AUTOSAR XML (schema 4-0-3)
standard types defined: uint8, Boolean, UInt16, UInt8
package /AUTOSAR_Platform/DataConstrs
  range DC_Boolean: raw 0..1
  range DC_UInt16: raw 0..65535
  range DC_UInt8: raw 0..255
package /DataTypes/Units
  unit NoUnit1: display-name=NoUnit, factor-si-to-unit=1, offset-si-to-unit=0
package /PATAC/Facility/DataTypes/Implementation
  compu method COMPU_Boolean: 0=FALSE, 1=TRUE
  unit NoUnit: factor-si-to-unit=1, offset-si-to-unit=0
package /PATAC/MSM/DataTypes/ImplementationDataTypes
  impl type IfVeSMSeStNumConfig: category=VALUE, base-type=UInt8, sw-calibration-access=READ-ONLY, compu {0=SeatNum4Config, 1=SeatNum6Config, 2=SeatNum7Config, 3=SeatNum4PConfig, 4=SeatNumNDLBLow, 5=SeatNumNDLBHigh}, type-emitter=RTE
package /PATAC/MSM/ModeAdjust
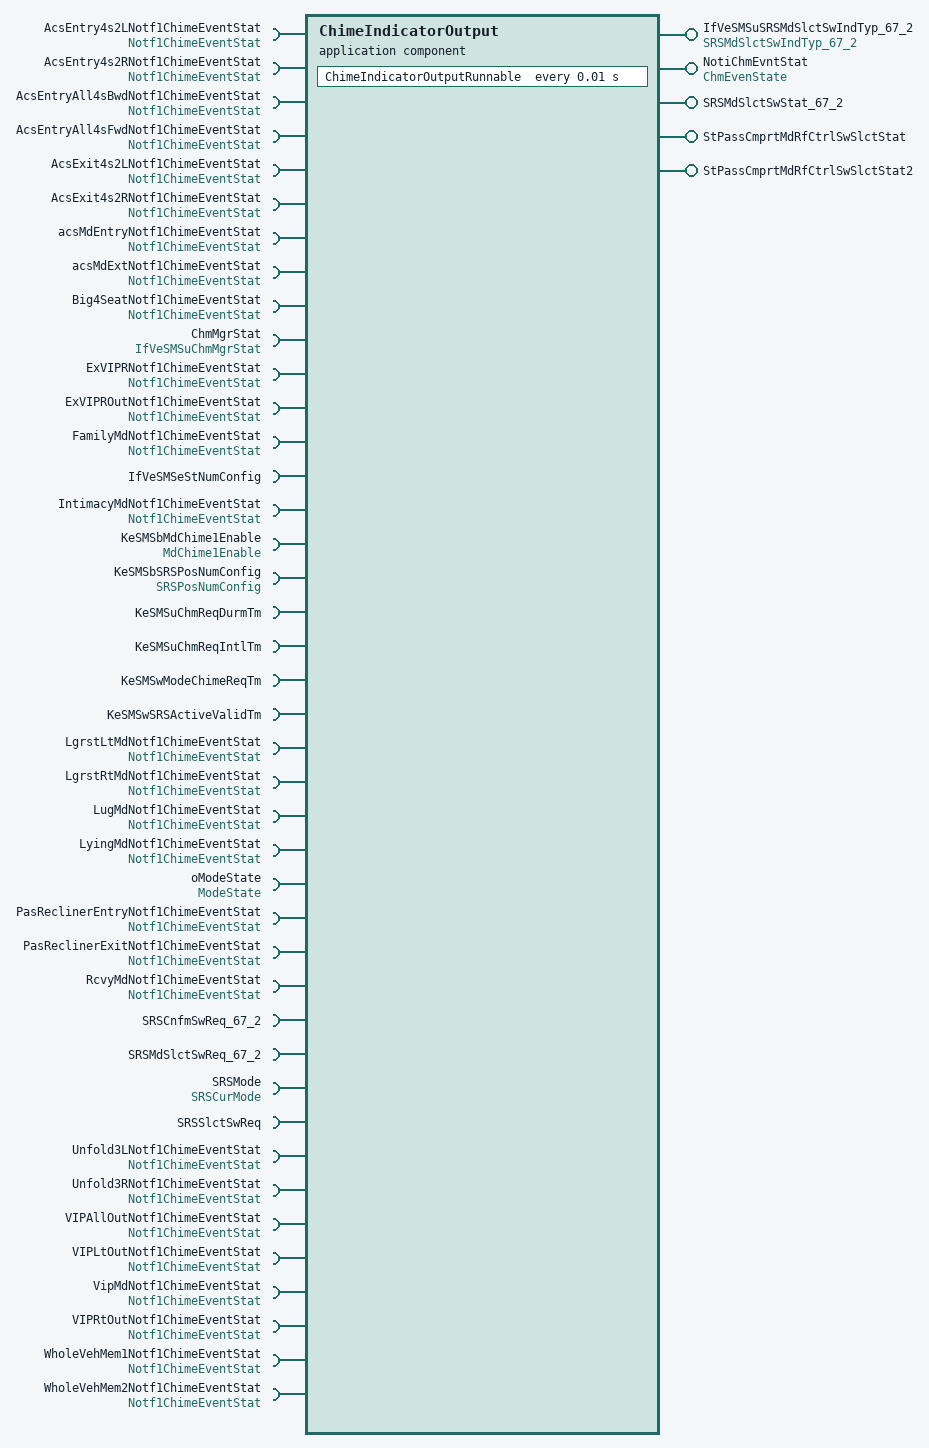
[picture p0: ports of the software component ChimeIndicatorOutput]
  application sw component type ChimeIndicatorOutput
    5 x provide port:
      IfVeSMSuSRSMdSlctSwIndTyp_67_2: nonqueued-sender-com-spec{data-element=SRSMdSlctSwIndTyp_67_2/Val, init-value=1}, provided-interface=SRSMdSlctSwIndTyp_67_2
      NotiChmEvntStat: nonqueued-sender-com-spec{data-element=ChmEvenState/Val, init-value=0}, provided-interface=ChmEvenState
      SRSMdSlctSwStat_67_2: nonqueued-sender-com-spec{data-element=SRSMdSlctSwStat_67_2/Val, init-value=0}, provided-interface=SRSMdSlctSwStat_67_2
      StPassCmprtMdRfCtrlSwSlctStat: nonqueued-sender-com-spec{data-element=StPassCmprtMdRfCtrlSwSlctStat/Val, init-value=0}, provided-interface=StPassCmprtMdRfCtrlSwSlctStat
      StPassCmprtMdRfCtrlSwSlctStat2: nonqueued-sender-com-spec{data-element=StPassCmprtMdRfCtrlSwSlctStat2/Val, init-value=0}, provided-interface=StPassCmprtMdRfCtrlSwSlctStat2
    41 x require port:
      AcsEntry4s2LNotf1ChimeEventStat: nonqueued-receiver-com-spec{data-element=Notf1ChimeEventStat/Val, filter=data-filter-type=ALWAYS, init-value=ComSpeceda9e3ad_0fc6068a0470d301:0}, required-interface=Notf1ChimeEventStat
      AcsEntry4s2RNotf1ChimeEventStat: nonqueued-receiver-com-spec{data-element=Notf1ChimeEventStat/Val, filter=data-filter-type=ALWAYS, init-value=ComSpec8c573e42_0f1c7c18a14dbf66:0}, required-interface=Notf1ChimeEventStat
      AcsEntryAll4sBwdNotf1ChimeEventStat: nonqueued-receiver-com-spec{data-element=Notf1ChimeEventStat/Val, filter=data-filter-type=ALWAYS, init-value=ComSpec37c91717_b8c9f7bc704ff9d2:0}, required-interface=Notf1ChimeEventStat
      AcsEntryAll4sFwdNotf1ChimeEventStat: nonqueued-receiver-com-spec{data-element=Notf1ChimeEventStat/Val, filter=data-filter-type=ALWAYS, init-value=ComSpecd15f079f_e85a705a3cb0df53:0}, required-interface=Notf1ChimeEventStat
      AcsExit4s2LNotf1ChimeEventStat: nonqueued-receiver-com-spec{data-element=Notf1ChimeEventStat/Val, filter=data-filter-type=ALWAYS, init-value=ComSpec6bd96ec8_afd24b1b20c88edf:0}, required-interface=Notf1ChimeEventStat
      AcsExit4s2RNotf1ChimeEventStat: nonqueued-receiver-com-spec{data-element=Notf1ChimeEventStat/Val, filter=data-filter-type=ALWAYS, init-value=ComSpec9c4cc562_0f5ef71d88f0fd04:0}, required-interface=Notf1ChimeEventStat
      acsMdEntryNotf1ChimeEventStat: nonqueued-receiver-com-spec{data-element=Notf1ChimeEventStat/Val, filter=data-filter-type=ALWAYS, init-value=0}, required-interface=Notf1ChimeEventStat
      acsMdExtNotf1ChimeEventStat: nonqueued-receiver-com-spec{data-element=Notf1ChimeEventStat/Val, filter=data-filter-type=ALWAYS, init-value=ComSpec24494de9_edfa97ce43be2a3a:0}, required-interface=Notf1ChimeEventStat
      Big4SeatNotf1ChimeEventStat: nonqueued-receiver-com-spec{data-element=Notf1ChimeEventStat/Val, filter=data-filter-type=ALWAYS, init-value=0}, required-interface=Notf1ChimeEventStat
      ChmMgrStat: nonqueued-receiver-com-spec{data-element=IfVeSMSuChmMgrStat/Val, filter=data-filter-type=ALWAYS, init-value=ComSpec0ceab9e4_4a33521a3ee1a770:2}, required-interface=IfVeSMSuChmMgrStat
      ExVIPRNotf1ChimeEventStat: nonqueued-receiver-com-spec{data-element=Notf1ChimeEventStat/Val, filter=data-filter-type=ALWAYS, init-value=0}, required-interface=Notf1ChimeEventStat
      ExVIPROutNotf1ChimeEventStat: nonqueued-receiver-com-spec{data-element=Notf1ChimeEventStat/Val, filter=data-filter-type=ALWAYS, init-value=0}, required-interface=Notf1ChimeEventStat
      FamilyMdNotf1ChimeEventStat: nonqueued-receiver-com-spec{data-element=Notf1ChimeEventStat/Val, filter=data-filter-type=ALWAYS, init-value=ComSpec92b47237_cd009972311b2162:0}, required-interface=Notf1ChimeEventStat
      IfVeSMSeStNumConfig: nonqueued-receiver-com-spec{data-element=IfVeSMSeStNumConfig/Val, filter=data-filter-type=ALWAYS, init-value=2}, required-interface=IfVeSMSeStNumConfig
      IntimacyMdNotf1ChimeEventStat: nonqueued-receiver-com-spec{data-element=Notf1ChimeEventStat/Val, filter=data-filter-type=ALWAYS, init-value=ComSpec3c33feb1_9314e4783a6c11b5:0}, required-interface=Notf1ChimeEventStat
      KeSMSbMdChime1Enable: parameter-require-com-spec{init-value=KeSMSbMdChime1Enable_Val:0, parameter=MdChime1Enable/Val}, required-interface=MdChime1Enable
      KeSMSbSRSPosNumConfig: parameter-require-com-spec{init-value=4, parameter=SRSPosNumConfig/Val}, required-interface=SRSPosNumConfig
      KeSMSuChmReqDurmTm: parameter-require-com-spec{init-value=KeSMSuChmReqDurmTm_Val:200, parameter=KeSMSuChmReqDurmTm/Val}, required-interface=KeSMSuChmReqDurmTm
      KeSMSuChmReqIntlTm: parameter-require-com-spec{init-value=KeSMSuChmReqIntlTm_Val:50, parameter=KeSMSuChmReqIntlTm/Val}, required-interface=KeSMSuChmReqIntlTm
      KeSMSwModeChimeReqTm: parameter-require-com-spec{init-value=KeSMSwModeChimeReqTm_Val:500, parameter=KeSMSwModeChimeReqTm/Val}, required-interface=KeSMSwModeChimeReqTm
      KeSMSwSRSActiveValidTm: parameter-require-com-spec{init-value=KeSMSwSRSActiveValidTm_Val:500, parameter=KeSMSwSRSActiveValidTm/Val}, required-interface=KeSMSwSRSActiveValidTm
      LgrstLtMdNotf1ChimeEventStat: nonqueued-receiver-com-spec{data-element=Notf1ChimeEventStat/Val, filter=data-filter-type=ALWAYS, init-value=ComSpecac8d8dad_acf652ffb0cb1279:0}, required-interface=Notf1ChimeEventStat
      LgrstRtMdNotf1ChimeEventStat: nonqueued-receiver-com-spec{data-element=Notf1ChimeEventStat/Val, filter=data-filter-type=ALWAYS, init-value=ComSpec3d6065d3_a539af7cf0176c3f:0}, required-interface=Notf1ChimeEventStat
      LugMdNotf1ChimeEventStat: nonqueued-receiver-com-spec{data-element=Notf1ChimeEventStat/Val, filter=data-filter-type=ALWAYS, init-value=ComSpec7c5dd238_74e99c6277d5e641:0}, required-interface=Notf1ChimeEventStat
      LyingMdNotf1ChimeEventStat: nonqueued-receiver-com-spec{data-element=Notf1ChimeEventStat/Val, filter=data-filter-type=ALWAYS, init-value=ComSpecd8b8ae0e_83cb297b15cbea14:0}, required-interface=Notf1ChimeEventStat
      oModeState: nonqueued-receiver-com-spec{data-element=ModeState/Val, filter=data-filter-type=ALWAYS, init-value=0}, required-interface=ModeState
      PasReclinerEntryNotf1ChimeEventStat: nonqueued-receiver-com-spec{data-element=Notf1ChimeEventStat/Val, filter=data-filter-type=ALWAYS, init-value=ComSpec7e4d3edc_7acc9f8f2009e728:0}, required-interface=Notf1ChimeEventStat
      PasReclinerExitNotf1ChimeEventStat: nonqueued-receiver-com-spec{data-element=Notf1ChimeEventStat/Val, filter=data-filter-type=ALWAYS, init-value=ComSpec9f4ab2cf_5d7cafcfdff2af21:0}, required-interface=Notf1ChimeEventStat
      RcvyMdNotf1ChimeEventStat: nonqueued-receiver-com-spec{data-element=Notf1ChimeEventStat/Val, filter=data-filter-type=ALWAYS, init-value=ComSpece6a37631_464cf6f791a15f13:0}, required-interface=Notf1ChimeEventStat
      SRSCnfmSwReq_67_2: nonqueued-receiver-com-spec{data-element=SRSCnfmSwReq_67_2/Val, filter=data-filter-type=ALWAYS, init-value=ComSpec9325e9e8_f7fd9485b93f3ffd:0}, required-interface=SRSCnfmSwReq_67_2
      SRSMdSlctSwReq_67_2: nonqueued-receiver-com-spec{data-element=SRSMdSlctSwReq_67_2/Val, filter=data-filter-type=ALWAYS, init-value=0}, required-interface=SRSMdSlctSwReq_67_2
      SRSMode: nonqueued-receiver-com-spec{data-element=SRSCurMode/Val, filter=data-filter-type=ALWAYS, init-value=0}, required-interface=SRSCurMode
      SRSSlctSwReq: nonqueued-receiver-com-spec{data-element=SRSSlctSwReq/Val, filter=data-filter-type=ALWAYS, init-value=0}, required-interface=SRSSlctSwReq
      Unfold3LNotf1ChimeEventStat: nonqueued-receiver-com-spec{data-element=Notf1ChimeEventStat/Val, filter=data-filter-type=ALWAYS, init-value=ComSpecd4722a82_9dfecf2406bed3a2:0}, required-interface=Notf1ChimeEventStat
      Unfold3RNotf1ChimeEventStat: nonqueued-receiver-com-spec{data-element=Notf1ChimeEventStat/Val, filter=data-filter-type=ALWAYS, init-value=ComSpec42213ac2_e56d2450b57cadc3:0}, required-interface=Notf1ChimeEventStat
      VIPAllOutNotf1ChimeEventStat: nonqueued-receiver-com-spec{data-element=Notf1ChimeEventStat/Val, filter=data-filter-type=ALWAYS, init-value=ComSpeccc961ebe_a596b23fd04396d1:0}, required-interface=Notf1ChimeEventStat
      VIPLtOutNotf1ChimeEventStat: nonqueued-receiver-com-spec{data-element=Notf1ChimeEventStat/Val, filter=data-filter-type=ALWAYS, init-value=ComSpecd5d8d36a_66b3bc886f3170c5:0}, required-interface=Notf1ChimeEventStat
      VipMdNotf1ChimeEventStat: nonqueued-receiver-com-spec{data-element=Notf1ChimeEventStat/Val, filter=data-filter-type=ALWAYS, init-value=ComSpec89e941d0_21fb21470bdd5603:0}, required-interface=Notf1ChimeEventStat
      VIPRtOutNotf1ChimeEventStat: nonqueued-receiver-com-spec{data-element=Notf1ChimeEventStat/Val, filter=data-filter-type=ALWAYS, init-value=ComSpec834e1dd5_b69ddf5dd0ce9610:0}, required-interface=Notf1ChimeEventStat
      WholeVehMem1Notf1ChimeEventStat: nonqueued-receiver-com-spec{data-element=Notf1ChimeEventStat/Val, filter=data-filter-type=ALWAYS, init-value=0}, required-interface=Notf1ChimeEventStat
      WholeVehMem2Notf1ChimeEventStat: nonqueued-receiver-com-spec{data-element=Notf1ChimeEventStat/Val, filter=data-filter-type=ALWAYS, init-value=0}, required-interface=Notf1ChimeEventStat
    behavior ChimeIndicatorOutput_InternalBehavior
      timing event TMT_ChimeIndicatorOutputRunnable: start-on-event=ChimeIndicatorOutputRunnable, period=0.01
      runnable ChimeIndicatorOutputRunnable: minimum-start-interval=0.01
        data-receive-point-by-arguments:
          35 x access:
            REC_AcsEntry4s2LNotf1ChimeEventStat_Val: accessed-variable=AcsEntry4s2LNotf1ChimeEventStat.Val
            REC_AcsEntry4s2RNotf1ChimeEventStat_Val: accessed-variable=AcsEntry4s2RNotf1ChimeEventStat.Val
            REC_AcsEntryAll4sBwdNotf1ChimeEventStat_Val: accessed-variable=AcsEntryAll4sBwdNotf1ChimeEventStat.Val
            REC_AcsEntryAll4sFwdNotf1ChimeEventStat_Val: accessed-variable=AcsEntryAll4sFwdNotf1ChimeEventStat.Val
            REC_AcsExit4s2LNotf1ChimeEventStat_Val: accessed-variable=AcsExit4s2LNotf1ChimeEventStat.Val
            REC_AcsExit4s2RNotf1ChimeEventStat_Val: accessed-variable=AcsExit4s2RNotf1ChimeEventStat.Val
            REC_acsMdEntryNotf1ChimeEventStat_Val: accessed-variable=acsMdEntryNotf1ChimeEventStat.Val
            REC_acsMdExtNotf1ChimeEventStat_Val: accessed-variable=acsMdExtNotf1ChimeEventStat.Val
            REC_Big4SeatNotf1ChimeEventStat_Val: accessed-variable=Big4SeatNotf1ChimeEventStat.Val
            REC_ChmMgrStat_Val: accessed-variable=ChmMgrStat.Val
            REC_ExVIPRNotf1ChimeEventStat_Val: accessed-variable=ExVIPRNotf1ChimeEventStat.Val
            REC_ExVIPROutNotf1ChimeEventStat_Val: accessed-variable=ExVIPROutNotf1ChimeEventStat.Val
            REC_FamilyMdNotf1ChimeEventStat_Val: accessed-variable=FamilyMdNotf1ChimeEventStat.Val
            REC_IfVeSMSeStNumConfig_Val: accessed-variable=IfVeSMSeStNumConfig.Val
            REC_IntimacyMdNotf1ChimeEventStat_Val: accessed-variable=IntimacyMdNotf1ChimeEventStat.Val
            REC_LgrstLtMdNotf1ChimeEventStat_Val: accessed-variable=LgrstLtMdNotf1ChimeEventStat.Val
            REC_LgrstRtMdNotf1ChimeEventStat_Val: accessed-variable=LgrstRtMdNotf1ChimeEventStat.Val
            REC_LugMdNotf1ChimeEventStat_Val: accessed-variable=LugMdNotf1ChimeEventStat.Val
            REC_LyingMdNotf1ChimeEventStat_Val: accessed-variable=LyingMdNotf1ChimeEventStat.Val
            REC_oModeState_Val: accessed-variable=oModeState.Val
            REC_PasReclinerEntryNotf1ChimeEventStat_Val: accessed-variable=PasReclinerEntryNotf1ChimeEventStat.Val
            REC_PasReclinerExitNotf1ChimeEventStat_Val: accessed-variable=PasReclinerExitNotf1ChimeEventStat.Val
            REC_RcvyMdNotf1ChimeEventStat_Val: accessed-variable=RcvyMdNotf1ChimeEventStat.Val
            REC_SRSCnfmSwReq_67_2_Val: accessed-variable=SRSCnfmSwReq_67_2.Val
            REC_SRSMdSlctSwReq_67_2_Val: accessed-variable=SRSMdSlctSwReq_67_2.Val
            REC_SRSMode_Val: accessed-variable=SRSMode.Val
            REC_SRSSlctSwReq_Val: accessed-variable=SRSSlctSwReq.Val
            REC_Unfold3LNotf1ChimeEventStat_Val: accessed-variable=Unfold3LNotf1ChimeEventStat.Val
            REC_Unfold3RNotf1ChimeEventStat_Val: accessed-variable=Unfold3RNotf1ChimeEventStat.Val
            REC_VIPAllOutNotf1ChimeEventStat_Val: accessed-variable=VIPAllOutNotf1ChimeEventStat.Val
            REC_VIPLtOutNotf1ChimeEventStat_Val: accessed-variable=VIPLtOutNotf1ChimeEventStat.Val
            REC_VipMdNotf1ChimeEventStat_Val: accessed-variable=VipMdNotf1ChimeEventStat.Val
            REC_VIPRtOutNotf1ChimeEventStat_Val: accessed-variable=VIPRtOutNotf1ChimeEventStat.Val
            REC_WholeVehMem1Notf1ChimeEventStat_Val: accessed-variable=WholeVehMem1Notf1ChimeEventStat.Val
            REC_WholeVehMem2Notf1ChimeEventStat_Val: accessed-variable=WholeVehMem2Notf1ChimeEventStat.Val
        data-send-points:
          5 x access:
            SEND_IfVeSMSuSRSMdSlctSwIndTyp_67_2_Val: accessed-variable=IfVeSMSuSRSMdSlctSwIndTyp_67_2.Val
            SEND_NotiChmEvntStat_Val: accessed-variable=NotiChmEvntStat.Val
            SEND_SRSMdSlctSwStat_67_2_Val: accessed-variable=SRSMdSlctSwStat_67_2.Val
            SEND_StPassCmprtMdRfCtrlSwSlctStat_Val: accessed-variable=StPassCmprtMdRfCtrlSwSlctStat.Val
            SEND_StPassCmprtMdRfCtrlSwSlctStat2_Val: accessed-variable=StPassCmprtMdRfCtrlSwSlctStat2.Val
        6 x parameter access:
          PA_KeSMSbMdChime1Enable_Val: accessed-parameter=KeSMSbMdChime1Enable.Val
          PA_KeSMSbSRSPosNumConfig_Val: accessed-parameter=KeSMSbSRSPosNumConfig.Val
          PA_KeSMSuChmReqDurmTm_Val: accessed-parameter=KeSMSuChmReqDurmTm.Val
          PA_KeSMSuChmReqIntlTm_Val: accessed-parameter=KeSMSuChmReqIntlTm.Val
          PA_KeSMSwModeChimeReqTm_Val: accessed-parameter=KeSMSwModeChimeReqTm.Val
          PA_KeSMSwSRSActiveValidTm_Val: accessed-parameter=KeSMSwSRSActiveValidTm.Val
  swc implementation ChimeIndicatorOutput_Implementation: behavior=ChimeIndicatorOutput_InternalBehavior
    code-descriptors:
      code Default: artifact-descriptors=autosar-engineering-object={short-label=Default, category=SWSRC}
package /PATAC/MSM/ModeAdjust/CalPortInterface
  6 x parameter interface:
    KeSMSuChmReqDurmTm
      parameter data prototype Val: sw-calibration-access=READ-WRITE, type=UInt8
    KeSMSuChmReqIntlTm
      parameter data prototype Val: sw-calibration-access=READ-WRITE, type=UInt8
    KeSMSwModeChimeReqTm
      parameter data prototype Val: sw-calibration-access=READ-WRITE, type=UInt16
    KeSMSwSRSActiveValidTm
      parameter data prototype Val: sw-calibration-access=READ-WRITE, type=UInt16
    MdChime1Enable
      parameter data prototype Val: sw-calibration-access=READ-WRITE, type=Boolean
    SRSPosNumConfig
      parameter data prototype Val: sw-calibration-access=READ-WRITE, type=UInt8
package /PATAC/MSM/ModeAdjust/DataType
  9 x impl type, all with category=VALUE, base-type=UInt8, sw-calibration-access=READ-ONLY, type-emitter=RTE:
    CmprtMdRfCtrlSwSlctStat1: compu {0=NoModeOn, 1=Mode1On, 2=Mode2On, 3=Mode3On, 4=Mode4On, 5=Mode5On, 6=Mode6On, 7=Mode7On, 8=Mode8On, 9=Mode9On, 10=Mode10On, 11=Mode11On, 12=Mode12On, 13=Mode13On, 14=Mode14On, 15=Mode15On}
    CmprtMdRfCtrlSwSlctStat2: compu {0=NoModeOn1, 1=Mode16On, 2=Mode17On, 3=Mode18On, 4=Mode19On, 5=Mode20On, 6=Mode21On, 7=Mode22On, 8=Mode23On, 9=Mode24On, 10=Mode25On, 11=Mode26On, 12=Mode27On, 13=Mode28On, 14=Mode29On, 15=Mode30On, 16=Mode31On, 17=Mode32On}
    EventSts1: compu {0=EventSts_NoAct, 1=EventSts_Act, 2=EventSts_CancleChime}
    MdTp1: compu {0=MdTp_None, 1=MdTp_EzeEntry, 2=MdTp_EzeExt, 3=MdTp_Vip, 4=MdTp_Lug, 5=MdTp_Recovery, 6=MdTp_Intimacy, 7=MdTp_Family, 8=MdTp_Lying, 9=MdTp_LgrstOpenLt, 10=MdTp_LgrstCloseLt, 11=MdTp_LgrstOpenRt, 12=MdTp_LgrstCloseRt}
    SRSCurMode1: compu {0=SRSMode_None, 1=SRSMode_EZEEntry, 2=SRSMode_EzeExt, 3=SRSMode_LfVip, 4=SRSMode_RtVip, 5=SRSMode_AllVip, 6=SRSMode_LfLug, 7=SRSMode_RtLug, 8=SRSMode_AllLug, 9=SRSMode_IntimacyL, 10=SRSMode_FamilyR, 11=SRSMode_FamilyL, 12=SRSMode_RcvyL, 13=SRSMode_RcvyR, 14=SRSMode_LyingL, 15=SRSMode_LyingR, 16=SRSMode_LgrstOpenLt, 17=SRSMode_LgrstCloseLt, 18=SRSMode_LgrstOpenRt, 19=SRSMode_LgrstCloseRt, 20=SRSMode_IntimacyR, 21=SRSMode_EzeEntry4s2L, 22=SRSMode_EzeExt4s2L, 23=SRSMode_EzeEntry4s2R, 24=SRSMode_EzeExt4s2R, 25=SRSMode_EzeEntryAll4sBwd, 26=SRSMode_EzeEntryAll4sFwd}
    SRSIndicatorStat: compu {0=SRSIndicatorStat_NoIndicator, 1=SRSIndicatorStat_Mode1On, 2=SRSIndicatorStat_Mode2On, 3=SRSIndicatorStat_Mode3On, 4=SRSIndicatorStat_Mode4On, 5=SRSIndicatorStat_Mode5On, 6=SRSIndicatorStat_Mode6On, 7=SRSIndicatorStat_Mode7On, 8=SRSIndicatorStat_Mode8On, 9=SRSIndicatorStat_Mode9On, 10=SRSIndicatorStat_Mode10On, 11..15=Reserved1..Reserved5}
    SRSMode1: compu {0=SRSSlctSwStat_None, 1=SRSSlctSwStat_EzeEntry, 2=SRSSlctSwStat_EzeExt, 3=SRSSlctSwStat_LfVip, 4=SRSSlctSwStat_RtVip, 5=SRSSlctSwStat_AllVip, 6=SRSSlctSwStat_LfLug, 7=SRSSlctSwStat_RtLug, 8=SRSSlctSwStat_AllLug, 9=SRSSlctSwStat_IntimacyL, 10=SRSSlctSwStat_FamilyR, 11=SRSSlctSwStat_FamilyL, 12=SRSSlctSwStat_RcvyL, 13=SRSSlctSwStat_RcvyR, 14=SRSSlctSwStat_LyingL, 15=SRSSlctSwStat_LyingR, 16=SRSSlctSwStat_LgrstOpenLt, 17=SRSSlctSwStat_LgrstCloseLt, 18=SRSSlctSwStat_LgrstOpenRt, 19=SRSSlctSwStat_LgrstCloseRt, 20=SRSSlctSwStat_IntimacyR, 21=SRSSlctSwStat_EzeEntry4s2L, 22=SRSSlctSwStat_EzeExt4s2L, 23=SRSSlctSwStat_EzeEntry4s2R, 24=SRSSlctSwStat_EzeExt4s2R, 25=SRSSlctSwStat_EzeEntryAll4sBwd, 26=SRSSlctSwStat_EzeEntryAll4sFwd}
    SRSSlctSwIndTyp: compu {0=IndicationOff, 1=FlashRate1, 2=FlashRate2, 3=Continuous}
    SRSSlctSwStat1: compu {0=NoSwitchSelected, 1=Switch1Mode, 2=Switch2Mode, 3=Switch3Mode, 4=Switch4Mode, 5=Switch5Mode, 6=Switch6Mode, 7=Switch7Mode, 8=Switch8Mode, 9=Switch9Mode, 10=Switch10Mode, 11=Reserved}
package /PATAC/MSM/ModeAdjust/Interfaces
  sender receiver interface IfVeSMSuChmMgrStat: invalidation-policy{data-element=IfVeSMSuChmMgrStat/Val, handle-invalid=DONT-INVALIDATE}
    data Val: type=UInt16
package /PATAC/MSM/ModeAdjust/PortInterface
  12 x sender receiver interface:
    ChmEvenState: invalidation-policy{data-element=ChmEvenState/Val, handle-invalid=DONT-INVALIDATE}
      data Val: type=EventSts1
    IfVeSMSeStNumConfig: invalidation-policy{data-element=IfVeSMSeStNumConfig/Val, handle-invalid=DONT-INVALIDATE}
      data Val: type=IfVeSMSeStNumConfig
    ModeState: invalidation-policy{data-element=ModeState/Val, handle-invalid=DONT-INVALIDATE}
      data Val: type=MdTp1
    Notf1ChimeEventStat: invalidation-policy{data-element=Notf1ChimeEventStat/Val, handle-invalid=DONT-INVALIDATE}
      data Val: type=Boolean
    SRSCnfmSwReq_67_2: invalidation-policy{data-element=SRSCnfmSwReq_67_2/Val, handle-invalid=DONT-INVALIDATE}
      data Val: type=Boolean
    SRSCurMode: invalidation-policy{data-element=SRSCurMode/Val, handle-invalid=DONT-INVALIDATE}
      data Val: type=SRSCurMode1
    SRSMdSlctSwIndTyp_67_2: invalidation-policy{data-element=SRSMdSlctSwIndTyp_67_2/Val, handle-invalid=DONT-INVALIDATE}
      data Val: type=SRSSlctSwIndTyp
    SRSMdSlctSwReq_67_2: invalidation-policy{data-element=SRSMdSlctSwReq_67_2/Val, handle-invalid=DONT-INVALIDATE}
      data Val: type=SRSSlctSwStat1
    SRSMdSlctSwStat_67_2: invalidation-policy{data-element=SRSMdSlctSwStat_67_2/Val, handle-invalid=DONT-INVALIDATE}
      data Val: type=SRSIndicatorStat
    SRSSlctSwReq: invalidation-policy{data-element=SRSSlctSwReq/Val, handle-invalid=DONT-INVALIDATE}
      data Val: type=SRSMode1
    StPassCmprtMdRfCtrlSwSlctStat: invalidation-policy{data-element=StPassCmprtMdRfCtrlSwSlctStat/Val, handle-invalid=DONT-INVALIDATE}
      data Val: type=CmprtMdRfCtrlSwSlctStat1
    StPassCmprtMdRfCtrlSwSlctStat2: invalidation-policy{data-element=StPassCmprtMdRfCtrlSwSlctStat2/Val, handle-invalid=DONT-INVALIDATE}
      data Val: type=CmprtMdRfCtrlSwSlctStat2
